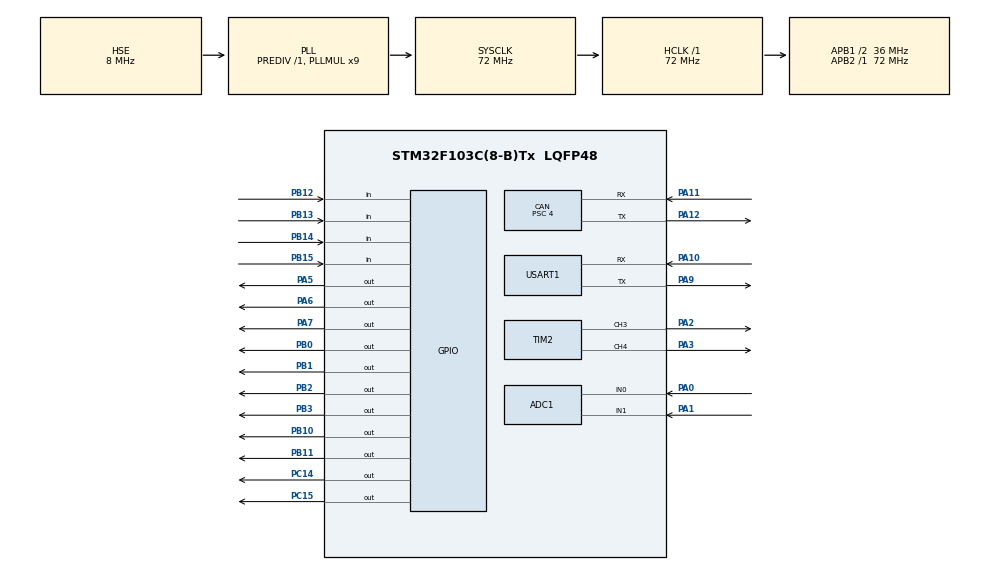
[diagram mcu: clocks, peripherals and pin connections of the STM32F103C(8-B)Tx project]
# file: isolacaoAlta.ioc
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Mcu.Family=STM32F1
NVIC.ADC1_2_IRQn=true\:0\:0\:false\:false\:true\:true\:true
Dma.USART1_TX.2.Direction=DMA_MEMORY_TO_PERIPH
NVIC.CAN1_RX1_IRQn=true\:0\:0\:false\:false\:true\:true\:true
NVIC.DMA1_Channel5_IRQn=true\:0\:0\:false\:false\:true\:false\:true
ADC1.ContinuousConvMode=ENABLE
PA11.Mode=CAN_Activate
PA7.GPIO_ModeDefaultOutputPP=GPIO_MODE_OUTPUT_OD
PB11.Signal=GPIO_Output
PB13.Signal=GPIO_Input
PB15.Signal=GPIO_Input
RCC.SYSCLKSource=RCC_SYSCLKSOURCE_PLLCLK
ProjectManager.StackSize=0x400
PD1-OSC_OUT.Signal=RCC_OSC_OUT
PB10.GPIO_ModeDefaultOutputPP=GPIO_MODE_OUTPUT_OD
PA12.Signal=CAN_TX
NVIC.USB_HP_CAN1_TX_IRQn=true\:0\:0\:false\:false\:true\:true\:true
CAN.Prescaler=4
RCC.HCLKFreq_Value=72000000
RCC.APB2TimFreq_Value=72000000
Dma.ADC1.0.Direction=DMA_PERIPH_TO_MEMORY
Dma.USART1_RX.1.MemInc=DMA_MINC_ENABLE
Dma.ADC1.0.MemDataAlignment=DMA_MDATAALIGN_WORD
RCC.AHBFreq_Value=72000000
ADC1.Channel-0\#ChannelRegularConversion=ADC_CHANNEL_0
Dma.USART1_RX.1.PeriphDataAlignment=DMA_PDATAALIGN_BYTE
PB2.Signal=GPIO_Output
RCC.PLLMUL=RCC_PLL_MUL9
PA14.Mode=Serial_Wire
Dma.ADC1.0.PeriphInc=DMA_PINC_DISABLE
Dma.USART1_TX.2.PeriphDataAlignment=DMA_PDATAALIGN_BYTE
SH.ADCx_IN0.0=ADC1_IN0,IN0
Dma.USART1_TX.2.MemDataAlignment=DMA_MDATAALIGN_BYTE
CAN.CalculateTimeQuantum=111.11111111111111
ADC1.SamplingTime-0\#ChannelRegularConversion=ADC_SAMPLETIME_1CYCLE_5
Dma.USART1_RX.1.Mode=DMA_NORMAL
Mcu.Package=LQFP48
PB1.Signal=GPIO_Output
PA6.Signal=GPIO_Output
PA10.Signal=USART1_RX
Dma.USART1_RX.1.PeriphInc=DMA_PINC_DISABLE
PA6.GPIO_ModeDefaultOutputPP=GPIO_MODE_OUTPUT_OD
SH.ADCx_IN1.0=ADC1_IN1,IN1
Dma.Request2=USART1_TX
Dma.Request1=USART1_RX
RCC.APB1TimFreq_Value=72000000
PB0.GPIO_ModeDefaultOutputPP=GPIO_MODE_OUTPUT_OD
Dma.USART1_RX.1.Priority=DMA_PRIORITY_LOW
NVIC.DMA1_Channel4_IRQn=true\:0\:0\:false\:false\:true\:false\:true
Dma.Request0=ADC1
PB2.GPIO_ModeDefaultOutputPP=GPIO_MODE_OUTPUT_OD
PA3.Signal=S_TIM2_CH4
RCC.PLLSourceVirtual=RCC_PLLSOURCE_HSE
Dma.USART1_RX.1.Instance=DMA1_Channel5
TIM2.Channel-PWM\ Generation4\ CH4=TIM_CHANNEL_4
Dma.ADC1.0.Instance=DMA1_Channel1
Dma.USART1_RX.1.MemDataAlignment=DMA_MDATAALIGN_BYTE
ADC1.Rank-0\#ChannelRegularConversion=1
PD1-OSC_OUT.Mode=HSE-External-Oscillator
PA10.Mode=Asynchronous
Dma.USART1_TX.2.MemInc=DMA_MINC_ENABLE
CAN.CalculateBaudRate=500000
PD0-OSC_IN.Signal=RCC_OSC_IN
RCC.APB1CLKDivider=RCC_HCLK_DIV2
PC14-OSC32_IN.Signal=GPIO_Output
CAN.CalculateTimeBit=1999.99
PA0-WKUP.Signal=ADCx_IN0
RCC.ADCPresc=RCC_ADCPCLK2_DIV6
PA13.Signal=SYS_JTMS-SWDIO
Dma.ADC1.0.PeriphDataAlignment=DMA_PDATAALIGN_WORD
PA9.Mode=Asynchronous
CAN.BS2=CAN_BS2_2TQ
CAN.BS1=CAN_BS1_15TQ
ProjectManager.TargetToolchain=STM32CubeIDE
Dma.ADC1.0.Mode=DMA_CIRCULAR
Dma.ADC1.0.Priority=DMA_PRIORITY_LOW
PA9.Signal=USART1_TX
ADC1.Channel-1\#ChannelRegularConversion=ADC_CHANNEL_1
RCC.USBFreq_Value=72000000
PC15-OSC32_OUT.Signal=GPIO_Output
PA1.Signal=ADCx_IN1
PB11.GPIO_ModeDefaultOutputPP=GPIO_MODE_OUTPUT_OD
PD0-OSC_IN.Mode=HSE-External-Oscillator
PB10.Signal=GPIO_Output
PB14.Signal=GPIO_Input
PA5.Signal=GPIO_Output
board=custom
RCC.APB2Freq_Value=72000000
PA5.GPIO_ModeDefaultOutputPP=GPIO_MODE_OUTPUT_OD
SH.S_TIM2_CH3.0=TIM2_CH3,PWM Generation3 CH3
Dma.USART1_TX.2.Priority=DMA_PRIORITY_LOW
NVIC.USB_LP_CAN1_RX0_IRQn=true\:0\:0\:false\:false\:true\:true\:true
TIM2.Channel-PWM\ Generation3\ CH3=TIM_CHANNEL_3
ADC1.NbrOfConversion=2
PA13.Mode=Serial_Wire
Mcu.Name=STM32F103C(8-B)Tx
PA2.Signal=S_TIM2_CH3
Dma.USART1_TX.2.PeriphInc=DMA_PINC_DISABLE
PB3.Signal=GPIO_Output
ADC1.SamplingTime-1\#ChannelRegularConversion=ADC_SAMPLETIME_1CYCLE_5
RCC.SYSCLKFreq_VALUE=72000000
ADC1.master=1
PA12.Mode=CAN_Activate
USART1.VirtualMode=VM_ASYNC
ADC1.Rank-1\#ChannelRegularConversion=2
PA11.Signal=CAN_RX
PA14.Signal=SYS_JTCK-SWCLK
Dma.ADC1.0.MemInc=DMA_MINC_ENABLE
ProjectManager.HeapSize=0x200
SH.S_TIM2_CH4.0=TIM2_CH4,PWM Generation4 CH4
Dma.USART1_TX.2.Mode=DMA_NORMAL
NVIC.PriorityGroup=NVIC_PRIORITYGROUP_4
ADC1.NbrOfConversionFlag=1
Dma.USART1_TX.2.Instance=DMA1_Channel4
Dma.USART1_RX.1.Direction=DMA_PERIPH_TO_MEMORY
NVIC.DMA1_Channel1_IRQn=true\:0\:0\:false\:false\:true\:false\:true
PB1.GPIO_ModeDefaultOutputPP=GPIO_MODE_OUTPUT_OD
RCC.APB1Freq_Value=36000000
PB0.Signal=GPIO_Output
PB12.Signal=GPIO_Input
PA7.Signal=GPIO_Output

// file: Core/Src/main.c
/* USER CODE BEGIN Header */
/**
  ******************************************************************************
  * @file           : main.c
  * @brief          : Main program body
  ******************************************************************************
  * @attention
  *
  * <h2><center>&copy; Copyright (c) 2021 STMicroelectronics.
  * All rights reserved.</center></h2>
  *
  * This software component is licensed by ST under BSD 3-Clause license,
  * the "License"; You may not use this file except in compliance with the
  * License. You may obtain a copy of the License at:
  *                        opensource.org/licenses/BSD-3-Clause
  *
  ******************************************************************************
  */
/* USER CODE END Header */
#include "main.h"

void SystemClock_Config(void);
static void MX_GPIO_Init(void);
static void MX_DMA_Init(void);
static void MX_CAN_Init(void);
static void MX_USART1_UART_Init(void);
static void MX_ADC1_Init(void);
static void MX_TIM2_Init(void);

int main(void)
{

  /* MCU Configuration--------------------------------------------------------*/

  /* Reset of all peripherals, Initializes the Flash interface and the Systick. */
  HAL_Init();

  /* Configure the system clock */
  SystemClock_Config();

  /* Initialize all configured peripherals */
  MX_GPIO_Init();
  MX_DMA_Init();
  MX_CAN_Init();
  MX_USART1_UART_Init();
  MX_ADC1_Init();
  MX_TIM2_Init();
  setup();

  /* Infinite loop */
  /* USER CODE BEGIN WHILE */
  loop();
  /* USER CODE END 3 */
}

void SystemClock_Config(void)
{
  RCC_OscInitTypeDef RCC_OscInitStruct = {0};
  RCC_ClkInitTypeDef RCC_ClkInitStruct = {0};
  RCC_PeriphCLKInitTypeDef PeriphClkInit = {0};

  /** Initializes the RCC Oscillators according to the specified parameters
  * in the RCC_OscInitTypeDef structure.
  */
  RCC_OscInitStruct.OscillatorType = RCC_OSCILLATORTYPE_HSE;
  RCC_OscInitStruct.HSEState = RCC_HSE_ON;
  RCC_OscInitStruct.HSEPredivValue = RCC_HSE_PREDIV_DIV1;
  RCC_OscInitStruct.HSIState = RCC_HSI_ON;
  RCC_OscInitStruct.PLL.PLLState = RCC_PLL_ON;
  RCC_OscInitStruct.PLL.PLLSource = RCC_PLLSOURCE_HSE;
  RCC_OscInitStruct.PLL.PLLMUL = RCC_PLL_MUL9;
  if (HAL_RCC_OscConfig(&RCC_OscInitStruct) != HAL_OK)
  {
    Error_Handler();
  }
  /** Initializes the CPU, AHB and APB buses clocks
  */
  RCC_ClkInitStruct.ClockType = RCC_CLOCKTYPE_HCLK|RCC_CLOCKTYPE_SYSCLK
                              |RCC_CLOCKTYPE_PCLK1|RCC_CLOCKTYPE_PCLK2;
  RCC_ClkInitStruct.SYSCLKSource = RCC_SYSCLKSOURCE_PLLCLK;
  RCC_ClkInitStruct.AHBCLKDivider = RCC_SYSCLK_DIV1;
  RCC_ClkInitStruct.APB1CLKDivider = RCC_HCLK_DIV2;
  RCC_ClkInitStruct.APB2CLKDivider = RCC_HCLK_DIV1;

  if (HAL_RCC_ClockConfig(&RCC_ClkInitStruct, FLASH_LATENCY_2) != HAL_OK)
  {
    Error_Handler();
  }
  PeriphClkInit.PeriphClockSelection = RCC_PERIPHCLK_ADC;
  PeriphClkInit.AdcClockSelection = RCC_ADCPCLK2_DIV6;
  if (HAL_RCCEx_PeriphCLKConfig(&PeriphClkInit) != HAL_OK)
  {
    Error_Handler();
  }
}

static void MX_ADC1_Init(void)
{

  ADC_ChannelConfTypeDef sConfig = {0};

  /** Common config
  */
  hadc1.Instance = ADC1;
  hadc1.Init.ScanConvMode = ADC_SCAN_ENABLE;
  hadc1.Init.ContinuousConvMode = ENABLE;
  hadc1.Init.DiscontinuousConvMode = DISABLE;
  hadc1.Init.ExternalTrigConv = ADC_SOFTWARE_START;
  hadc1.Init.DataAlign = ADC_DATAALIGN_RIGHT;
  hadc1.Init.NbrOfConversion = 2;
  if (HAL_ADC_Init(&hadc1) != HAL_OK)
  {
    Error_Handler();
  }
  /** Configure Regular Channel
  */
  sConfig.Channel = ADC_CHANNEL_0;
  sConfig.Rank = ADC_REGULAR_RANK_1;
  sConfig.SamplingTime = ADC_SAMPLETIME_1CYCLE_5;
  if (HAL_ADC_ConfigChannel(&hadc1, &sConfig) != HAL_OK)
  {
    Error_Handler();
  }
  /** Configure Regular Channel
  */
  sConfig.Channel = ADC_CHANNEL_1;
  sConfig.Rank = ADC_REGULAR_RANK_2;
  if (HAL_ADC_ConfigChannel(&hadc1, &sConfig) != HAL_OK)
  {
    Error_Handler();
  }

}

static void MX_CAN_Init(void)
{

  hcan.Instance = CAN1;
  hcan.Init.Prescaler = 4;
  hcan.Init.Mode = CAN_MODE_NORMAL;
  hcan.Init.SyncJumpWidth = CAN_SJW_1TQ;
  hcan.Init.TimeSeg1 = CAN_BS1_15TQ;
  hcan.Init.TimeSeg2 = CAN_BS2_2TQ;
  hcan.Init.TimeTriggeredMode = DISABLE;
  hcan.Init.AutoBusOff = DISABLE;
  hcan.Init.AutoWakeUp = DISABLE;
  hcan.Init.AutoRetransmission = DISABLE;
  hcan.Init.ReceiveFifoLocked = DISABLE;
  hcan.Init.TransmitFifoPriority = DISABLE;
  if (HAL_CAN_Init(&hcan) != HAL_OK)
  {
    Error_Handler();
  }

}

static void MX_TIM2_Init(void)
{

  TIM_MasterConfigTypeDef sMasterConfig = {0};
  TIM_OC_InitTypeDef sConfigOC = {0};

  htim2.Instance = TIM2;
  htim2.Init.Prescaler = 0;
  htim2.Init.CounterMode = TIM_COUNTERMODE_UP;
  htim2.Init.Period = 65535;
  htim2.Init.ClockDivision = TIM_CLOCKDIVISION_DIV1;
  htim2.Init.AutoReloadPreload = TIM_AUTORELOAD_PRELOAD_DISABLE;
  if (HAL_TIM_PWM_Init(&htim2) != HAL_OK)
  {
    Error_Handler();
  }
  sMasterConfig.MasterOutputTrigger = TIM_TRGO_RESET;
  sMasterConfig.MasterSlaveMode = TIM_MASTERSLAVEMODE_DISABLE;
  if (HAL_TIMEx_MasterConfigSynchronization(&htim2, &sMasterConfig) != HAL_OK)
  {
    Error_Handler();
  }
  sConfigOC.OCMode = TIM_OCMODE_PWM1;
  sConfigOC.Pulse = 0;
  sConfigOC.OCPolarity = TIM_OCPOLARITY_HIGH;
  sConfigOC.OCFastMode = TIM_OCFAST_DISABLE;
  if (HAL_TIM_PWM_ConfigChannel(&htim2, &sConfigOC, TIM_CHANNEL_3) != HAL_OK)
  {
    Error_Handler();
  }
  if (HAL_TIM_PWM_ConfigChannel(&htim2, &sConfigOC, TIM_CHANNEL_4) != HAL_OK)
  {
    Error_Handler();
  }
  HAL_TIM_MspPostInit(&htim2);

}

static void MX_USART1_UART_Init(void)
{

  huart1.Instance = USART1;
  huart1.Init.BaudRate = 115200;
  huart1.Init.WordLength = UART_WORDLENGTH_8B;
  huart1.Init.StopBits = UART_STOPBITS_1;
  huart1.Init.Parity = UART_PARITY_NONE;
  huart1.Init.Mode = UART_MODE_TX_RX;
  huart1.Init.HwFlowCtl = UART_HWCONTROL_NONE;
  huart1.Init.OverSampling = UART_OVERSAMPLING_16;
  if (HAL_UART_Init(&huart1) != HAL_OK)
  {
    Error_Handler();
  }

}

static void MX_DMA_Init(void)
{

  /* DMA controller clock enable */
  __HAL_RCC_DMA1_CLK_ENABLE();

  /* DMA interrupt init */
  /* DMA1_Channel1_IRQn interrupt configuration */
  HAL_NVIC_SetPriority(DMA1_Channel1_IRQn, 0, 0);
  HAL_NVIC_EnableIRQ(DMA1_Channel1_IRQn);
  /* DMA1_Channel4_IRQn interrupt configuration */
  HAL_NVIC_SetPriority(DMA1_Channel4_IRQn, 0, 0);
  HAL_NVIC_EnableIRQ(DMA1_Channel4_IRQn);
  /* DMA1_Channel5_IRQn interrupt configuration */
  HAL_NVIC_SetPriority(DMA1_Channel5_IRQn, 0, 0);
  HAL_NVIC_EnableIRQ(DMA1_Channel5_IRQn);

}

static void MX_GPIO_Init(void)
{
  GPIO_InitTypeDef GPIO_InitStruct = {0};

  /* GPIO Ports Clock Enable */
  __HAL_RCC_GPIOC_CLK_ENABLE();
  __HAL_RCC_GPIOD_CLK_ENABLE();
  __HAL_RCC_GPIOA_CLK_ENABLE();
  __HAL_RCC_GPIOB_CLK_ENABLE();

  /*Configure GPIO pin Output Level */
  HAL_GPIO_WritePin(GPIOC, GPIO_PIN_14|GPIO_PIN_15, GPIO_PIN_RESET);

  /*Configure GPIO pin Output Level */
  HAL_GPIO_WritePin(GPIOA, GPIO_PIN_5|GPIO_PIN_6|GPIO_PIN_7, GPIO_PIN_RESET);

  /*Configure GPIO pin Output Level */
  HAL_GPIO_WritePin(GPIOB, GPIO_PIN_0|GPIO_PIN_1|GPIO_PIN_2|GPIO_PIN_10
                          |GPIO_PIN_11|GPIO_PIN_3, GPIO_PIN_RESET);

  /*Configure GPIO pins : PC14 PC15 */
  GPIO_InitStruct.Pin = GPIO_PIN_14|GPIO_PIN_15;
  GPIO_InitStruct.Mode = GPIO_MODE_OUTPUT_PP;
  GPIO_InitStruct.Pull = GPIO_NOPULL;
  GPIO_InitStruct.Speed = GPIO_SPEED_FREQ_LOW;
  HAL_GPIO_Init(GPIOC, &GPIO_InitStruct);

  /*Configure GPIO pins : PA5 PA6 PA7 */
  GPIO_InitStruct.Pin = GPIO_PIN_5|GPIO_PIN_6|GPIO_PIN_7;
  GPIO_InitStruct.Mode = GPIO_MODE_OUTPUT_OD;
  GPIO_InitStruct.Pull = GPIO_NOPULL;
  GPIO_InitStruct.Speed = GPIO_SPEED_FREQ_LOW;
  HAL_GPIO_Init(GPIOA, &GPIO_InitStruct);

  /*Configure GPIO pins : PB0 PB1 PB2 PB10
                           PB11 */
  GPIO_InitStruct.Pin = GPIO_PIN_0|GPIO_PIN_1|GPIO_PIN_2|GPIO_PIN_10
                          |GPIO_PIN_11;
  GPIO_InitStruct.Mode = GPIO_MODE_OUTPUT_OD;
  GPIO_InitStruct.Pull = GPIO_NOPULL;
  GPIO_InitStruct.Speed = GPIO_SPEED_FREQ_LOW;
  HAL_GPIO_Init(GPIOB, &GPIO_InitStruct);

  /*Configure GPIO pins : PB12 PB13 PB14 PB15 */
  GPIO_InitStruct.Pin = GPIO_PIN_12|GPIO_PIN_13|GPIO_PIN_14|GPIO_PIN_15;
  GPIO_InitStruct.Mode = GPIO_MODE_INPUT;
  GPIO_InitStruct.Pull = GPIO_NOPULL;
  HAL_GPIO_Init(GPIOB, &GPIO_InitStruct);

  /*Configure GPIO pin : PB3 */
  GPIO_InitStruct.Pin = GPIO_PIN_3;
  GPIO_InitStruct.Mode = GPIO_MODE_OUTPUT_PP;
  GPIO_InitStruct.Pull = GPIO_NOPULL;
  GPIO_InitStruct.Speed = GPIO_SPEED_FREQ_LOW;
  HAL_GPIO_Init(GPIOB, &GPIO_InitStruct);

}

void Error_Handler(void)
{
  /* USER CODE BEGIN Error_Handler_Debug */
  /* User can add his own implementation to report the HAL error return state */
  __disable_irq();
  while (1)
  {
//	  uint8_t saida[34] = {0};
//	  HAL_UART_Transmit(&huart1, saida ,sizeof(saida), 100);
  }
  /* USER CODE END Error_Handler_Debug */
}

/************************ (C) COPYRIGHT STMicroelectronics *****END OF FILE****/
